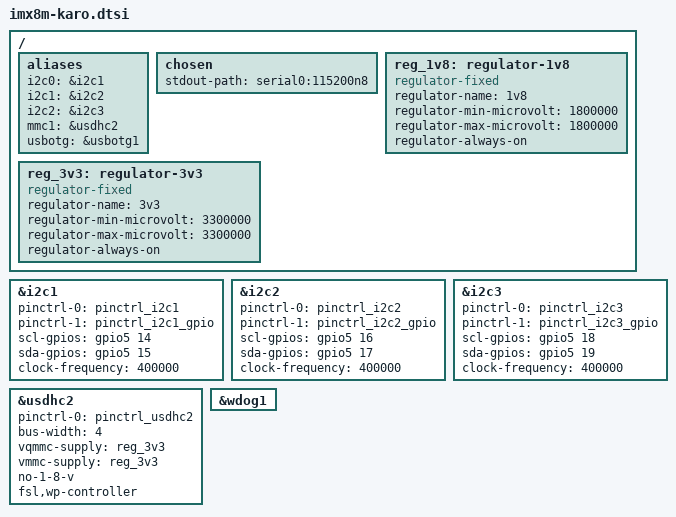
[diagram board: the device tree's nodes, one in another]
// SPDX-License-Identifier: (GPL-2.0 OR MIT)
/*
 * Copyright (C) 2023 Lothar Waßmann <LW@KARO-electronics.de>
 *
 */

/ {
	aliases {
		i2c0 = &i2c1;
		i2c1 = &i2c2;
		i2c2 = &i2c3;
		mmc1 = &usdhc2;
		usbotg = &usbotg1;
	};

	chosen {
		stdout-path = "serial0:115200n8";
	};

	reg_1v8: regulator-1v8 {
		compatible = "regulator-fixed";
		regulator-name = "1v8";
		regulator-min-microvolt = <1800000>;
		regulator-max-microvolt = <1800000>;
		regulator-always-on;
	};

	reg_3v3: regulator-3v3 {
		compatible = "regulator-fixed";
		regulator-name = "3v3";
		regulator-min-microvolt = <3300000>;
		regulator-max-microvolt = <3300000>;
		regulator-always-on;
	};
};

&i2c1 {
	pinctrl-names = "default", "gpio";
	pinctrl-0 = <&pinctrl_i2c1>;
	pinctrl-1 = <&pinctrl_i2c1_gpio>;
	scl-gpios = <&gpio5 14 GPIO_ACTIVE_HIGH>;
	sda-gpios = <&gpio5 15 GPIO_ACTIVE_HIGH>;
	clock-frequency = <400000>;
	status = "okay";
};

&i2c2 {
	pinctrl-names = "default", "gpio";
	pinctrl-0 = <&pinctrl_i2c2>;
	pinctrl-1 = <&pinctrl_i2c2_gpio>;
	scl-gpios = <&gpio5 16 GPIO_ACTIVE_HIGH>;
	sda-gpios = <&gpio5 17 GPIO_ACTIVE_HIGH>;
	clock-frequency = <400000>;
	status = "okay";
};

&i2c3 {
	pinctrl-names = "default", "gpio";
	pinctrl-0 = <&pinctrl_i2c3>;
	pinctrl-1 = <&pinctrl_i2c3_gpio>;
	scl-gpios = <&gpio5 18 GPIO_ACTIVE_HIGH>;
	sda-gpios = <&gpio5 19 GPIO_ACTIVE_HIGH>;
	clock-frequency = <400000>;
	status = "okay";
};

&usdhc2 {
	pinctrl-names = "default";
	pinctrl-0 = <&pinctrl_usdhc2>;
	bus-width = <4>;
	vqmmc-supply = <&reg_3v3>;
	vmmc-supply = <&reg_3v3>;
	no-1-8-v;
	fsl,wp-controller;
	status = "okay";
};

&wdog1 {
	status = "okay";
};
